# N32H7xx register map
Vendor: Nationstech Ltd.; File version: 1.0
CPU: CM7 r1p1, little endian, MPU, FPU, 4 interrupt priority bits
Registers are 32-bit, read-write, reset 0x0 unless marked. A register's access mark holds for its fields unless they carry their own. Offsets are from the block's base; [hi:lo] are bit positions; {n}, {i} and the like mark numbered series.

## SDMMC1 — Secure Digital MultiMedia Card
Base 0x51107000
Same registers: SDMMC2 0x4004A000
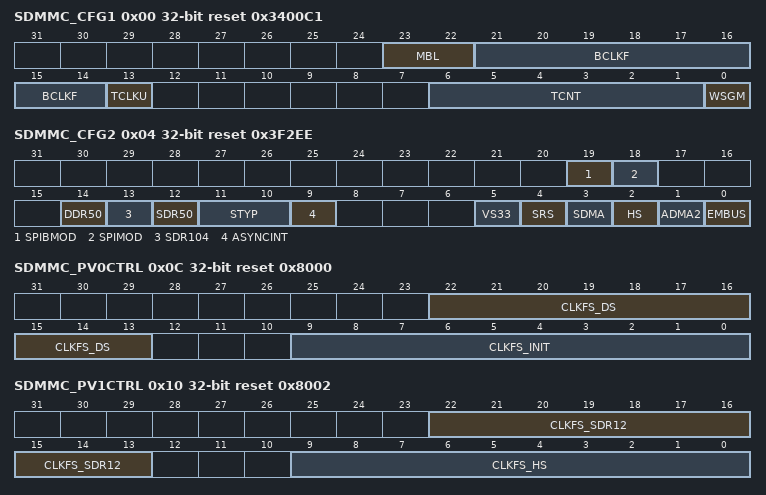
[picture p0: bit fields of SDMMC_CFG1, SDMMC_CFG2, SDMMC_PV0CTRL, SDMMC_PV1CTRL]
0x00 SDMMC_CFG1 reset 0x3400C1 — SDMMC Configuration Register1
  [23:22] MBL, [21:14] BCLKF, [13] TCLKU, [6:1] TCNT, [0] WSGM
0x04 SDMMC_CFG2 reset 0x3F2EE — SDMMC Configuration Register2
  [19] SPIBMOD, [18] SPIMOD, [14] DDR50, [13] SDR104, [12] SDR50, [11:10] STYP, [9] ASYNCINT, [5] VS33, [4] SRS, [3] SDMA, [2] HS, [1] ADMA2, [0] EMBUS
0x08 SDMMC_CFG3 reset 0x13 — SDMMC Configuration Register3
  [4] UTFSDR50
0x0C SDMMC_PV0CTRL reset 0x8000 — SDMMC Configuration Register4
  [22:13] CLKFS_DS, [9:0] CLKFS_INIT
0x10 SDMMC_PV1CTRL reset 0x8002 — SDMMC Configuration Register5
  [22:13] CLKFS_SDR12, [9:0] CLKFS_HS
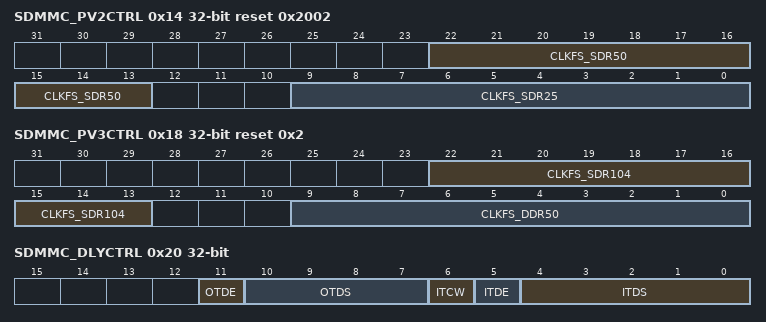
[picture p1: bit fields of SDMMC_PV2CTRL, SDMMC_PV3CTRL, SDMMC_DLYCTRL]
0x14 SDMMC_PV2CTRL reset 0x2002 — SDMMC Configuration Register6
  [22:13] CLKFS_SDR50, [9:0] CLKFS_SDR25
0x18 SDMMC_PV3CTRL reset 0x2 — SDMMC Configuration Register7
  [22:13] CLKFS_SDR104, [9:0] CLKFS_DDR50
0x20 SDMMC_DLYCTRL — SDMMC TX and RX Delay Control Register
  [11] OTDE, [10:7] OTDS, [6] ITCW, [5] ITDE, [4:0] ITDS

## SDHOST1 — Secure Digital MultiMedia Card
Base 0x51110000
Same registers: SDHOST2 0x40050000
0x00 SDHOST_DSADD — SDMA System Address / Argument 2
  [31:0] ADD
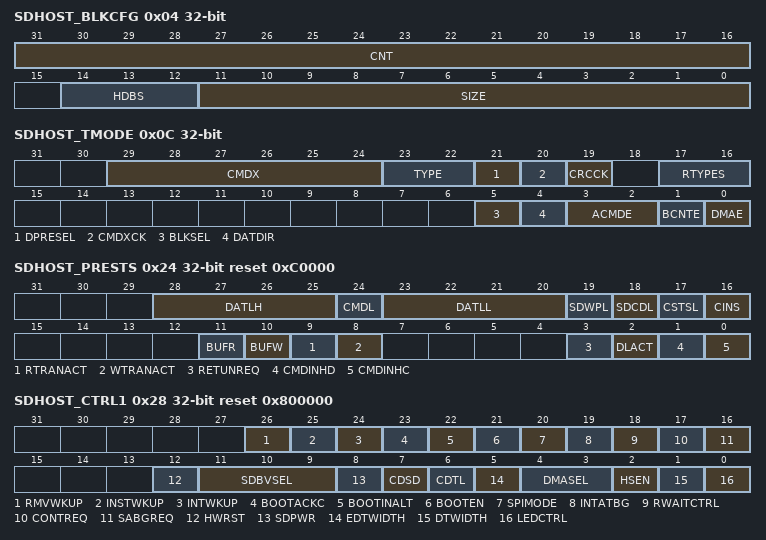
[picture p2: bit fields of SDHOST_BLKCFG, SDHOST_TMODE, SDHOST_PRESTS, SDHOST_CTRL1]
0x04 SDHOST_BLKCFG — Block count and size configure register
  [31:16] CNT, [14:12] HDBS, [11:0] SIZE
0x08 SDHOST_CMDARG1 — Argument1 register
  [31:0] ARG1
0x0C SDHOST_TMODE — nan
  [29:24] CMDX, [23:22] TYPE, [21] DPRESEL, [20] CMDXCK, [19] CRCCK, [17:16] RTYPES, [5] BLKSEL, [4] DATDIR, [3:2] ACMDE, [1] BCNTE, [0] DMAE
{0x10+4i} SDHOST_CMDRSP{i} ro (i=0..2) — Command Response 0
  [31:0] RESP{i}
0x1C SDHOST_CMDRSP3 ro — Command Response 0
  [31:0] RESP
0x20 SDHOST_BUFDAT — nan
  [31:0] DAT
0x24 SDHOST_PRESTS ro reset 0xC0000 — Present state register
  [28:25] DATLH, [24] CMDL, [23:20] DATLL, [19] SDWPL, [18] SDCDL, [17] CSTSL, [16] CINS, [11] BUFR, [10] BUFW, [9] RTRANACT, [8] WTRANACT, [3] RETUNREQ, [2] DLACT, [1] CMDINHD, [0] CMDINHC
0x28 SDHOST_CTRL1 reset 0x800000 — nan
  [26] RMVWKUP, [25] INSTWKUP, [24] INTWKUP, [23] BOOTACKC, [22] BOOTINALT, [21] BOOTEN, [20] SPIMODE, [19] INTATBG, [18] RWAITCTRL, [17] CONTREQ, [16] SABGREQ, [12] HWRST, [11:9] SDBVSEL, [8] SDPWR, [7] CDSD, [6] CDTL, [5] EDTWIDTH, [4:3] DMASEL, [2] HSEN, [1] DTWIDTH, [0] LEDCTRL
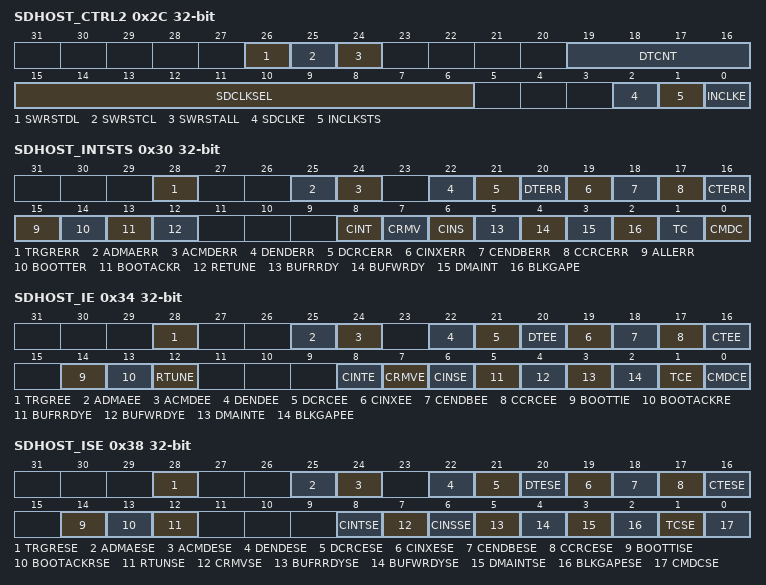
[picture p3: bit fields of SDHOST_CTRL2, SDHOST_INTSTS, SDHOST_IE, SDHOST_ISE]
0x2C SDHOST_CTRL2 — nan
  [26] SWRSTDL
  [25] SWRSTCL
  [24] SWRSTALL
  [19:16] DTCNT
  [15:6] SDCLKSEL — SDCLKSEL9_0
  [2] SDCLKE
  [1] INCLKSTS ro
  [0] INCLKE
0x30 SDHOST_INTSTS — nan
  [28] TRGRERR, [25] ADMAERR, [24] ACMDERR, [22] DENDERR, [21] DCRCERR, [20] DTERR, [19] CINXERR, [18] CENDBERR, [17] CCRCERR, [16] CTERR, [15] ALLERR ro, [14] BOOTTER, [13] BOOTACKR, [12] RETUNE ro, [8] CINT ro, [7] CRMV, [6] CINS, [5] BUFRRDY, [4] BUFWRDY, [3] DMAINT, [2] BLKGAPE, [1] TC, [0] CMDC
0x34 SDHOST_IE — nan
  [28] TRGREE, [25] ADMAEE, [24] ACMDEE, [22] DENDEE, [21] DCRCEE, [20] DTEE, [19] CINXEE, [18] CENDBEE, [17] CCRCEE, [16] CTEE, [14] BOOTTIE, [13] BOOTACKRE, [12] RTUNE, [8] CINTE, [7] CRMVE, [6] CINSE, [5] BUFRRDYE, [4] BUFWRDYE, [3] DMAINTE, [2] BLKGAPEE, [1] TCE, [0] CMDCE
0x38 SDHOST_ISE — nan
  [28] TRGRESE, [25] ADMAESE, [24] ACMDESE, [22] DENDESE, [21] DCRCESE, [20] DTESE, [19] CINXESE, [18] CENDBESE, [17] CCRCESE, [16] CTESE, [14] BOOTTISE, [13] BOOTACKRSE, [12] RTUNSE, [8] CINTSE, [7] CRMVSE, [6] CINSSE, [5] BUFRRDYSE, [4] BUFWRDYSE, [3] DMAINTSE, [2] BLKGAPESE, [1] TCSE, [0] CMDCSE
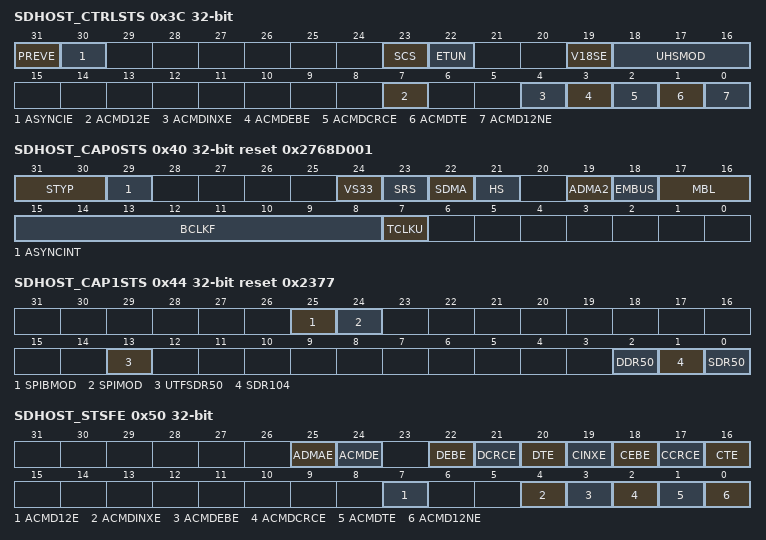
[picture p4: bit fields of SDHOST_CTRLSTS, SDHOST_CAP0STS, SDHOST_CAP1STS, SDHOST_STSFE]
0x3C SDHOST_CTRLSTS — nan
  [31] PREVE, [30] ASYNCIE, [23] SCS, [22] ETUN, [19] V18SE, [18:16] UHSMOD, [7] ACMD12E ro, [4] ACMDINXE ro, [3] ACMDEBE ro, [2] ACMDCRCE ro, [1] ACMDTE ro, [0] ACMD12NE ro
0x40 SDHOST_CAP0STS ro reset 0x2768D001 — nan
  [31:30] STYP, [29] ASYNCINT, [24] VS33, [23] SRS, [22] SDMA, [21] HS, [19] ADMA2, [18] EMBUS, [17:16] MBL, [15:8] BCLKF, [7] TCLKU
0x44 SDHOST_CAP1STS ro reset 0x2377 — nan
  [25] SPIBMOD, [24] SPIMOD, [13] UTFSDR50, [2] DDR50, [1] SDR104, [0] SDR50
0x50 SDHOST_STSFE wo — nan
  [25] ADMAE, [24] ACMDE, [22] DEBE, [21] DCRCE, [20] DTE, [19] CINXE, [18] CEBE, [17] CCRCE, [16] CTE, [7] ACMD12E, [4] ACMDINXE, [3] ACMDEBE, [2] ACMDCRCE, [1] ACMDTE, [0] ACMD12NE
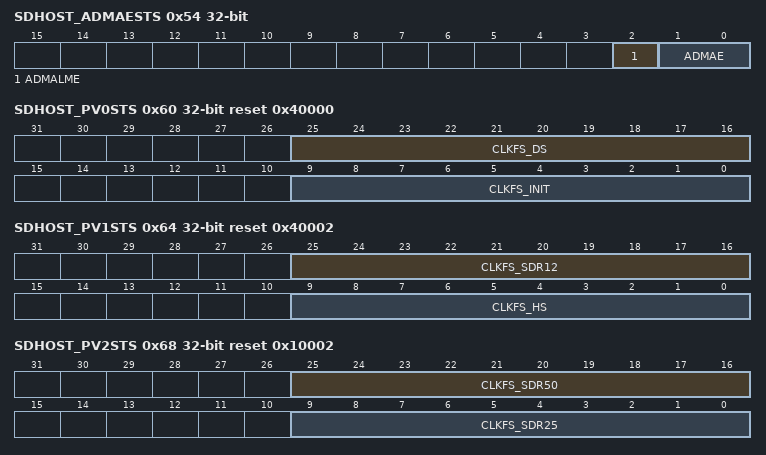
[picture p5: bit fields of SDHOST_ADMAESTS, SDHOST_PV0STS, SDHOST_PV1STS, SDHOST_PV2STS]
0x54 SDHOST_ADMAESTS ro — nan
  [2] ADMALME, [1:0] ADMAE
0x58 SDHOST_ASADD0 — nan
  [31:0] ADD
0x5C SDHOST_ASADD1 — nan
  [31:0] ADD
0x60 SDHOST_PV0STS ro reset 0x40000 — nan
  [25:16] CLKFS_DS, [9:0] CLKFS_INIT
0x64 SDHOST_PV1STS ro reset 0x40002 — nan
  [25:16] CLKFS_SDR12, [9:0] CLKFS_HS
0x68 SDHOST_PV2STS ro reset 0x10002 — nan
  [25:16] CLKFS_SDR50, [9:0] CLKFS_SDR25
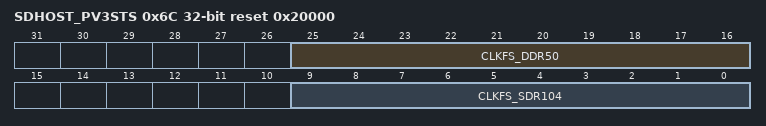
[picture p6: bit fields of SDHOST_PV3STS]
0x6C SDHOST_PV3STS ro reset 0x20000 — nan
  [25:16] CLKFS_DDR50, [9:0] CLKFS_SDR104
0x70 SDHOST_BOOTTCTRL — nan
  [31:0] CNT
